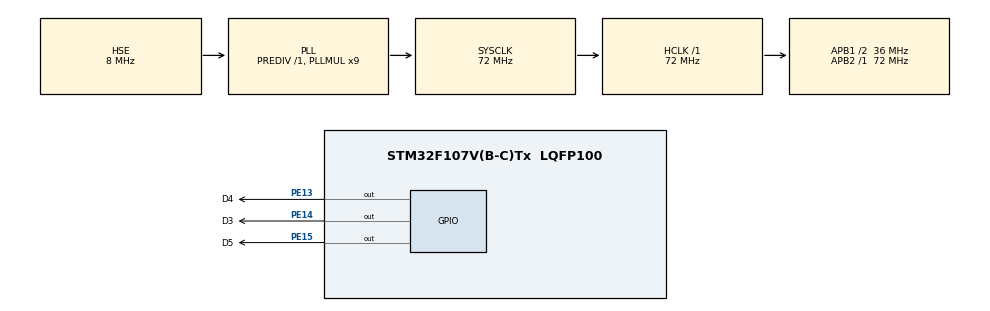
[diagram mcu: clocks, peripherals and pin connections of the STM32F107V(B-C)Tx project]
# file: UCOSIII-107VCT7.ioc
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FREERTOS.Tasks01=defaultTask,0,128,StartDefaultTask,Default,NULL
Mcu.Family=STM32F1
Mcu.Name=STM32F107V(B-C)Tx
Mcu.Package=LQFP100
NVIC.PriorityGroup=NVIC_PRIORITYGROUP_4
NVIC.TIM4_IRQn=true\:0\:0\:false\:false\:true\:false\:false
NVIC.TimeBase=TIM4_IRQn
NVIC.TimeBaseIP=TIM4
OSC_IN.Mode=HSE-External-Oscillator
OSC_IN.Signal=RCC_OSC_IN
OSC_OUT.Mode=HSE-External-Oscillator
OSC_OUT.Signal=RCC_OSC_OUT
PA13.Mode=Serial_Wire
PA13.Signal=SYS_JTMS-SWDIO
PA14.Mode=Serial_Wire
PA14.Signal=SYS_JTCK-SWCLK
PE13.GPIO_Label=D4
PE13.PinState=GPIO_PIN_SET
PE13.Signal=GPIO_Output
PE14.GPIO_Label=D3
PE14.PinState=GPIO_PIN_SET
PE14.Signal=GPIO_Output
PE15.GPIO_Label=D5
PE15.PinState=GPIO_PIN_SET
PE15.Signal=GPIO_Output
ProjectManager.HeapSize=0x200
ProjectManager.StackSize=0x400
ProjectManager.TargetToolchain=MDK-ARM V5
RCC.AHBFreq_Value=72000000
RCC.APB1CLKDivider=RCC_HCLK_DIV2
RCC.APB1Freq_Value=36000000
RCC.APB1TimFreq_Value=72000000
RCC.APB2Freq_Value=72000000
RCC.APB2TimFreq_Value=72000000
RCC.HCLKFreq_Value=72000000
RCC.PLLMUL=RCC_PLL_MUL9
RCC.PLLSourceVirtual=RCC_PLLSOURCE_HSE
RCC.SYSCLKFreq_VALUE=72000000
RCC.SYSCLKSource=RCC_SYSCLKSOURCE_PLLCLK
RCC.USBFreq_Value=48000000
VP_FREERTOS_VS_ENABLE.Mode=Enabled
VP_SYS_VS_tim4.Mode=TIM4
board=custom

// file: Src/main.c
/* USER CODE BEGIN Header */
/**
  ******************************************************************************
  * @file           : main.c
  * @brief          : Main program body
  ******************************************************************************
  * This notice applies to any and all portions of this file
  * that are not between comment pairs USER CODE BEGIN and
  * USER CODE END. Other portions of this file, whether
  * inserted by the user or by software development tools
  * are owned by their respective copyright owners.
  *
  * Copyright (c) 2019 STMicroelectronics International N.V.
  * All rights reserved.
  *
  * Redistribution and use in source and binary forms, with or without
  * modification, are permitted, provided that the following conditions are met:
  *
  * 1. Redistribution of source code must retain the above copyright notice,
  *    this list of conditions and the following disclaimer.
  * 2. Redistributions in binary form must reproduce the above copyright notice,
  *    this list of conditions and the following disclaimer in the documentation
  *    and/or other materials provided with the distribution.
  * 3. Neither the name of STMicroelectronics nor the names of other
  *    contributors to this software may be used to endorse or promote products
  *    derived from this software without specific written permission.
  * 4. This software, including modifications and/or derivative works of this
  *    software, must execute solely and exclusively on microcontroller or
  *    microprocessor devices manufactured by or for STMicroelectronics.
  * 5. Redistribution and use of this software other than as permitted under
  *    this license is void and will automatically terminate your rights under
  *    this license.
  *
  * THIS SOFTWARE IS PROVIDED BY STMICROELECTRONICS AND CONTRIBUTORS "AS IS"
  * AND ANY EXPRESS, IMPLIED OR STATUTORY WARRANTIES, INCLUDING, BUT NOT
  * LIMITED TO, THE IMPLIED WARRANTIES OF MERCHANTABILITY, FITNESS FOR A
  * PARTICULAR PURPOSE AND NON-INFRINGEMENT OF THIRD PARTY INTELLECTUAL PROPERTY
  * RIGHTS ARE DISCLAIMED TO THE FULLEST EXTENT PERMITTED BY LAW. IN NO EVENT
  * SHALL STMICROELECTRONICS OR CONTRIBUTORS BE LIABLE FOR ANY DIRECT, INDIRECT,
  * INCIDENTAL, SPECIAL, EXEMPLARY, OR CONSEQUENTIAL DAMAGES (INCLUDING, BUT NOT
  * LIMITED TO, PROCUREMENT OF SUBSTITUTE GOODS OR SERVICES; LOSS OF USE, DATA,
  * OR PROFITS; OR BUSINESS INTERRUPTION) HOWEVER CAUSED AND ON ANY THEORY OF
  * LIABILITY, WHETHER IN CONTRACT, STRICT LIABILITY, OR TORT (INCLUDING
  * NEGLIGENCE OR OTHERWISE) ARISING IN ANY WAY OUT OF THE USE OF THIS SOFTWARE,
  * EVEN IF ADVISED OF THE POSSIBILITY OF SUCH DAMAGE.
  *
  ******************************************************************************
  */
/* USER CODE END Header */

#include "main.h"
#include "cmsis_os.h"
#include "led.h"

osThreadId defaultTaskHandle;

void SystemClock_Config(void);
static void MX_GPIO_Init(void);
void StartDefaultTask(void const * argument);
void StartDefaultTask1(void const * argument);
void StartDefaultTask2(void const * argument);

int main(void)
{

  /* MCU Configuration--------------------------------------------------------*/

  /* Reset of all peripherals, Initializes the Flash interface and the Systick. */
  HAL_Init();

  /* Configure the system clock */
  SystemClock_Config();

  /* Initialize all configured peripherals */
  MX_GPIO_Init();

  /* Create the thread(s) */
  /* definition and creation of defaultTask */
  osThreadDef(defaultTask, StartDefaultTask, osPriorityNormal, 0, 128);
  defaultTaskHandle = osThreadCreate(osThread(defaultTask), NULL);

  /* USER CODE BEGIN RTOS_THREADS */
  /* add threads, ... */
  osThreadDef(defaultTask1, StartDefaultTask1, osPriorityNormal, 0, 128);
  defaultTaskHandle = osThreadCreate(osThread(defaultTask1), NULL);

  osThreadDef(defaultTask2, StartDefaultTask2, osPriorityNormal, 0, 128);
  defaultTaskHandle = osThreadCreate(osThread(defaultTask2), NULL);
  /* USER CODE END RTOS_THREADS */

  /* Start scheduler */
  osKernelStart();

  /* We should never get here as control is now taken by the scheduler */

  /* Infinite loop */
  while (1)
  {

  }
}

void SystemClock_Config(void)
{
  RCC_OscInitTypeDef RCC_OscInitStruct = {0};
  RCC_ClkInitTypeDef RCC_ClkInitStruct = {0};

  /**Initializes the CPU, AHB and APB busses clocks
  */
  RCC_OscInitStruct.OscillatorType = RCC_OSCILLATORTYPE_HSE;
  RCC_OscInitStruct.HSEState = RCC_HSE_ON;
  RCC_OscInitStruct.HSEPredivValue = RCC_HSE_PREDIV_DIV1;
  RCC_OscInitStruct.HSIState = RCC_HSI_ON;
  RCC_OscInitStruct.Prediv1Source = RCC_PREDIV1_SOURCE_HSE;
  RCC_OscInitStruct.PLL.PLLState = RCC_PLL_ON;
  RCC_OscInitStruct.PLL.PLLSource = RCC_PLLSOURCE_HSE;
  RCC_OscInitStruct.PLL.PLLMUL = RCC_PLL_MUL9;
  RCC_OscInitStruct.PLL2.PLL2State = RCC_PLL_NONE;
  if (HAL_RCC_OscConfig(&RCC_OscInitStruct) != HAL_OK)
  {
    Error_Handler();
  }
  /**Initializes the CPU, AHB and APB busses clocks
  */
  RCC_ClkInitStruct.ClockType = RCC_CLOCKTYPE_HCLK|RCC_CLOCKTYPE_SYSCLK
                              |RCC_CLOCKTYPE_PCLK1|RCC_CLOCKTYPE_PCLK2;
  RCC_ClkInitStruct.SYSCLKSource = RCC_SYSCLKSOURCE_PLLCLK;
  RCC_ClkInitStruct.AHBCLKDivider = RCC_SYSCLK_DIV1;
  RCC_ClkInitStruct.APB1CLKDivider = RCC_HCLK_DIV2;
  RCC_ClkInitStruct.APB2CLKDivider = RCC_HCLK_DIV1;

  if (HAL_RCC_ClockConfig(&RCC_ClkInitStruct, FLASH_LATENCY_2) != HAL_OK)
  {
    Error_Handler();
  }
  /**Configure the Systick interrupt time
  */
  __HAL_RCC_PLLI2S_ENABLE();
}

static void MX_GPIO_Init(void)
{
  GPIO_InitTypeDef GPIO_InitStruct = {0};

  /* GPIO Ports Clock Enable */
  __HAL_RCC_GPIOE_CLK_ENABLE();
  __HAL_RCC_GPIOA_CLK_ENABLE();

  /*Configure GPIO pin Output Level */
  HAL_GPIO_WritePin(GPIOE, D4_Pin|D3_Pin|D5_Pin, GPIO_PIN_SET);

  /*Configure GPIO pins : D4_Pin D3_Pin D5_Pin */
  GPIO_InitStruct.Pin = D4_Pin|D3_Pin|D5_Pin;
  GPIO_InitStruct.Mode = GPIO_MODE_OUTPUT_PP;
  GPIO_InitStruct.Pull = GPIO_NOPULL;
  GPIO_InitStruct.Speed = GPIO_SPEED_FREQ_LOW;
  HAL_GPIO_Init(GPIOE, &GPIO_InitStruct);

}

/* USER CODE BEGIN 4 */
void StartDefaultTask1(void const * argument)
{
	  while(1)
		{
			taskENTER_CRITICAL();
			TOGGLE_LED3();
			taskEXIT_CRITICAL();
			osDelay (1000);  //1s
		}
}

void StartDefaultTask2(void const * argument)
{
	  while(1)
		{
			taskENTER_CRITICAL();
			TOGGLE_LED4();
			TOGGLE_LED5();
			taskEXIT_CRITICAL();
			osDelay (500);  //1s
		}
}
/* USER CODE END 4 */

void StartDefaultTask(void const * argument)
{

  for(;;)
  {
    osDelay(1);
  }
}

void HAL_TIM_PeriodElapsedCallback(TIM_HandleTypeDef *htim)
{
  if (htim->Instance == TIM4) {
    HAL_IncTick();
  }
}

void Error_Handler(void)
{
}

/************************ (C) COPYRIGHT STMicroelectronics *****END OF FILE****/
